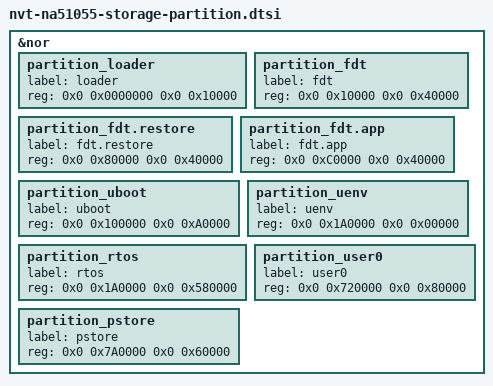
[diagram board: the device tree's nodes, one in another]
/*
 * Novatek Ltd. NA51055 BSP part of dts
 *
 * Cortex-A9
 *
 */

&nor {
	partition_loader {      label = "loader";       reg = <0x0 0x0000000 0x0 0x10000>;  }; /* Fixed */
	partition_fdt {	        label = "fdt";	        reg = <0x0 0x10000   0x0 0x40000>;  }; /* Fixed */
	partition_fdt.restore {	label = "fdt.restore";	reg = <0x0 0x80000   0x0 0x40000>;  }; /* Fixed */
	partition_fdt.app {     label = "fdt.app";      reg = <0x0 0xC0000   0x0 0x40000>;  };
	partition_uboot {       label = "uboot";        reg = <0x0 0x100000  0x0 0xA0000>;  };
	partition_uenv {        label = "uenv";         reg = <0x0 0x1A0000  0x0 0x00000>;  };
	partition_rtos {        label = "rtos";         reg = <0x0 0x1A0000  0x0 0x580000>; };
	partition_user0 {       label = "user0";        reg = <0x0 0x720000  0x0 0x80000>;  };
	partition_pstore {      label = "pstore";       reg = <0x0 0x7A0000  0x0 0x60000>;  };
	/*
	partition_pstore {      label = "pstore";       reg = <0x0 0x720000  0x0 0x60000>;  };
	partition_user0 {       label = "user0";        reg = <0x0 0x780000  0x0 0x80000>;  };
	*/
};
